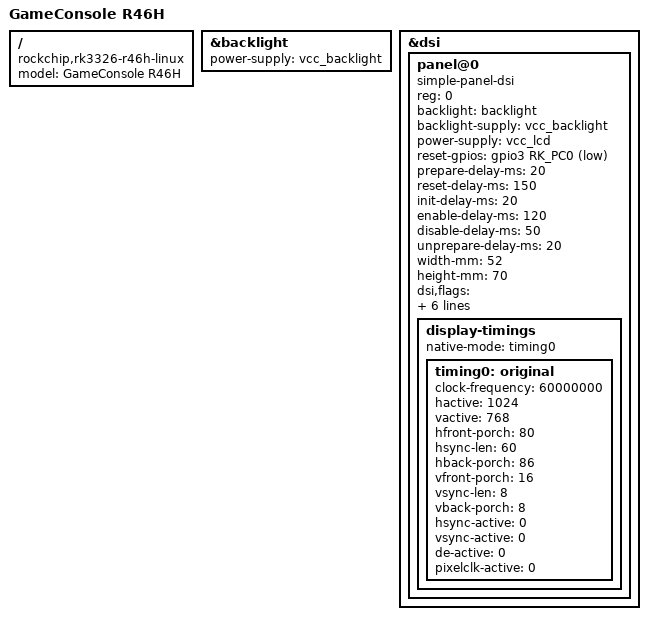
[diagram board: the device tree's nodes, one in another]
// SPDX-License-Identifier: (GPL-2.0+ OR MIT)
/*
* Copyright (c) 2026 kk&lcdyk
*
* GameConsole R46H
*
*/

/dts-v1/;
#include "rk3326-r36s-panel0-linux.dts"

/ {
	model = "GameConsole R46H";
	compatible = "rockchip,rk3326-r46h-linux", "rockchip,rk3326";
};

&backlight {
	power-supply = <&vcc_backlight>;
};

&dsi {
	status = "okay";
	
	panel@0 {
		compatible = "simple-panel-dsi";
		reg = <0>;
		/* pwm1 backlight */
		backlight = <&backlight>;
		/* RK817 LDO7 */
		backlight-supply = <&vcc_backlight>;
		/* RK817 LDO8 */
		power-supply = <&vcc_lcd>;
		/* Rev 0.2 LCD reset gpio GPIO3.C0 */
		reset-gpios = <&gpio3 RK_PC0 GPIO_ACTIVE_LOW>;
		prepare-delay-ms = <20>;
		reset-delay-ms = <150>;
		init-delay-ms = <20>;
		enable-delay-ms = <120>;
		disable-delay-ms = <50>;
		unprepare-delay-ms = <20>;
		width-mm = <52>;
		height-mm = <70>;
		dsi,flags  = <(MIPI_DSI_MODE_VIDEO |
		MIPI_DSI_MODE_VIDEO_BURST |
		MIPI_DSI_MODE_LPM |
		MIPI_DSI_MODE_EOT_PACKET)>;
		dsi,format = <MIPI_DSI_FMT_RGB888>;
		dsi,lanes = <4>;
		panel-init-sequence = [15 00 02 ee 01 15 00 02 ea 07 15 00 02 eb 12 15 00 02 0a 8b 15 00 02 17 35 15 00 02 1d 33 15 00 02 21 01 15 00 02 28 1c 15 00 02 29 27 15 00 02 2a 63 15 00 02 2b b5 15 00 02 2c 00 15 00 02 2d 33 15 00 02 2f f3 15 00 02 ee 02 15 00 02 39 78 15 00 02 39 78 15 00 02 00 00 15 00 02 01 18 15 00 02 02 15 15 00 02 03 10 15 00 02 04 18 15 00 02 05 3f 15 00 02 06 11 15 00 02 07 11 15 00 02 08 11 15 00 02 09 0f 15 00 02 0a 10 15 00 02 0b 54 15 00 02 0c 14 15 00 02 0d 17 15 00 02 0e 35 15 00 02 0f 37 15 00 02 10 3f 15 00 02 20 00 15 00 02 21 18 15 00 02 22 15 15 00 02 23 10 15 00 02 24 12 15 00 02 25 37 15 00 02 26 0b 15 00 02 27 0d 15 00 02 28 0d 15 00 02 29 0b 15 00 02 2a 10 15 00 02 2b 54 15 00 02 2c 14 15 00 02 2d 17 15 00 02 2e 35 15 00 02 2f 37 15 00 02 30 3f 15 00 02 ee 04 15 00 02 00 04 15 00 02 01 01 15 00 02 02 80 15 00 02 03 04 15 00 02 04 00 15 00 02 06 16 15 00 02 07 03 15 00 02 08 13 15 00 02 09 0a 15 00 02 0a 0f 15 00 02 0b 10 15 00 02 22 80 15 00 02 24 08 15 00 02 2a 00 15 00 02 ee 05 15 00 02 00 04 15 00 02 01 08 15 00 02 02 55 15 00 02 03 05 15 00 02 04 00 15 00 02 05 04 15 00 02 06 00 15 00 02 07 13 15 00 02 08 1e 15 00 02 09 66 15 00 02 0d 22 15 00 02 10 08 15 00 02 11 0c 15 00 02 12 55 15 00 02 13 05 15 00 02 19 14 15 00 02 1a 76 15 00 02 23 00 15 00 02 43 13 15 00 02 40 44 15 00 02 41 00 15 00 02 30 01 15 00 02 31 01 15 00 02 32 00 15 00 02 33 14 15 00 02 34 14 15 00 02 35 b4 15 00 02 36 01 15 00 02 37 01 15 00 02 38 00 15 00 02 39 14 15 00 02 3a 14 15 00 02 44 01 15 00 02 45 81 15 00 02 46 05 15 00 02 ee 06 15 00 02 00 23 15 00 02 01 01 15 00 02 02 04 15 00 02 06 cd 15 00 02 08 67 15 00 02 09 45 15 00 02 0a 23 15 00 02 0b 01 15 00 02 ee 07 15 00 02 00 3c 15 00 02 01 20 15 00 02 02 20 15 00 02 03 21 15 00 02 04 21 15 00 02 05 3c 15 00 02 06 3c 15 00 02 07 04 15 00 02 08 04 15 00 02 09 0c 15 00 02 0a 0c 15 00 02 0b 01 15 00 02 0c 15 15 00 02 0d 15 15 00 02 0e 17 15 00 02 0f 17 15 00 02 10 11 15 00 02 11 11 15 00 02 12 13 15 00 02 13 13 15 00 02 14 0d 15 00 02 15 0d 15 00 02 20 3c 15 00 02 21 20 15 00 02 22 20 15 00 02 23 21 15 00 02 24 21 15 00 02 25 3c 15 00 02 26 3c 15 00 02 27 04 15 00 02 28 04 15 00 02 29 0c 15 00 02 2a 0c 15 00 02 2b 00 15 00 02 2c 14 15 00 02 2d 14 15 00 02 2e 16 15 00 02 2f 16 15 00 02 30 10 15 00 02 31 10 15 00 02 32 12 15 00 02 33 12 15 00 02 34 0d 15 00 02 35 0d 15 00 02 ee 08 15 00 02 10 00 15 00 02 12 da 15 00 02 14 10 15 00 02 22 69 15 00 02 ee 0f 15 00 02 00 01 15 00 02 01 10 15 00 02 ee 00 15 00 02 ea 00 15 00 02 eb 00 05 c8 01 11 05 14 01 29];
		panel-exit-sequence = <0x5140128 0x50a0110>;
		
		display-timings {
			native-mode = <&timing0>;
			
			// 60.00MHz / (1024+80+60+86)×(768+16+8+8) = 1250×800 = 60.00 Hz
			timing0: original {
				clock-frequency = <60000000>;
				hactive = <1024>;
				vactive = <768>;
				hfront-porch = <80>;
				hsync-len = <60>;
				hback-porch = <86>;
				vfront-porch = <16>;
				vsync-len = <8>;
				vback-porch = <8>;
				hsync-active = <0>;
				vsync-active = <0>;
				de-active = <0>;
				pixelclk-active = <0>;
			};
		};
	};
};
